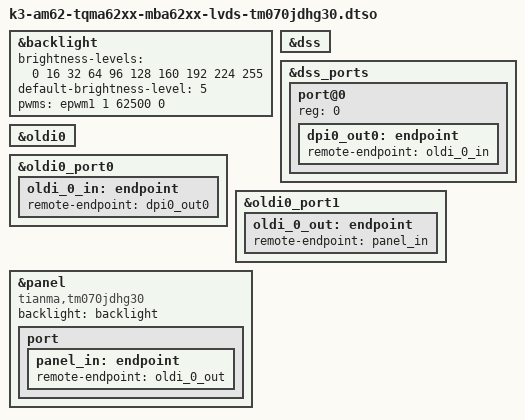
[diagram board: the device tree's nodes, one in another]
// SPDX-License-Identifier: GPL-2.0-only OR MIT
/*
 * Copyright (c) 2023-2026 TQ-Systems GmbH <linux@ew.tq-group.com>, D-82229 Seefeld, Germany.
 * Author: Nora Schiffer
 */

/dts-v1/;
/plugin/;

#include <dt-bindings/gpio/gpio.h>

&backlight {
	brightness-levels = <0 16 32 64 96 128 160 192 224 255>;
	default-brightness-level = <5>;
	pwms = <&epwm1 1 62500 0>;
	status = "okay";
};

&dss {
	status = "okay";
};

&dss_ports {
	#address-cells = <1>;
	#size-cells = <0>;

	port@0 {
		reg = <0>;

		dpi0_out0: endpoint {
			remote-endpoint = <&oldi_0_in>;
		};
	};
};

&oldi0 {
	status = "okay";
};

/* Mainline labels oldi0's two ports individually (oldi0_port0/1), not as a combined container. */
&oldi0_port0 {
	oldi_0_in: endpoint {
		remote-endpoint = <&dpi0_out0>;
	};
};

&oldi0_port1 {
	oldi_0_out: endpoint {
		remote-endpoint = <&panel_in>;
	};
};

&panel {
	compatible = "tianma,tm070jdhg30";
	backlight = <&backlight>;
	status = "okay";

	port {
		panel_in: endpoint {
			remote-endpoint = <&oldi_0_out>;
		};
	};
};
